# RX64M_DA_Pilot register map
File version: 1.0
RX64M_DA_Pilot peripheral registers generated from iodefine.h (pilot).
Registers are 8-bit, read-write, reset 0x0 unless marked. A register's access mark holds for its fields unless they carry their own. Offsets are from the block's base; lines under a group give offsets from that group; [hi:lo] are bit positions; {n}, {i} and the like mark numbered series; 'fields as' and 'values as' point back to an identical list; <NAME> marks a mode.

## Memory map
0x00088040 DA size 0x4581

## DA
Base 0x00088040
0x00 DADR0 16-bit
0x02 DADR1 16-bit
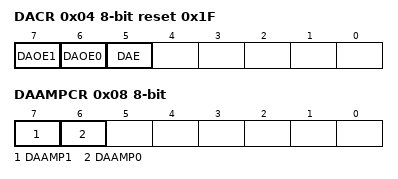
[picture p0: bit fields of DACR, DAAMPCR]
0x04 DACR reset 0x1F
  [7] DAOE1, [6] DAOE0, [5] DAE
0x05 DADPR
  [7] DPSEL
0x06 DAADSCR
  [7] DAADST
0x08 DAAMPCR
  [7] DAAMP1, [6] DAAMP0
0x4580 DAADUSR
  [1] AMADSEL1
